AUTOSAR XML (schema 4-3-0)
package /ComponentTypes
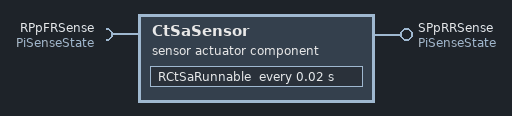
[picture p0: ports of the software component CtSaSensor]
  sensor actuator sw component type CtSaSensor
    require port RPpFRSense: nonqueued-receiver-com-spec{data-element=DePiSenseState, filter=data-filter-type=ALWAYS, init-value=0}, required-interface=PiSenseState
    provide port SPpRRSense: nonqueued-sender-com-spec{data-element=DePiSenseState, init-value=0}, provided-interface=PiSenseState
    behavior CtSaSensor_InternalBehavior: supports-multiple-instantiation=true
      timing event TMT_RCtSaRunnable: start-on-event=RCtSaRunnable, period=0.02
      runnable RCtSaRunnable
        data-receive-point-by-arguments:
          access REC_RPpFLSense_DePiSenseState: accessed-variable=RPpFRSense.DePiSenseState
        data-send-points:
          access SEND_SPpFLSense_DePiSenseState: accessed-variable=SPpRRSense.DePiSenseState
  swc implementation CtSaSensor_Implementation: behavior=CtSaSensor_InternalBehavior
